# F28x7x_eqep_regs register map
Vendor: Texas Instruments
Peripheral module from a debugger description file (folder C2000).
Address unit: 16 bits
Registers are 16-bit, read-write, no defined reset value unless marked. A register's access mark holds for its fields unless they carry their own. Offsets are as the file gives them; lines under a group give offsets from that group; [hi:lo] are bit positions; {n}, {i} and the like mark numbered series; 'fields as' and 'values as' point back to an identical list; <NAME> marks a mode.

## EQEP_REGS
0x00 QPOSCNT 32-bit — Position Counter
0x02 QPOSINIT 32-bit — Position Counter Init
0x04 QPOSMAX 32-bit — Maximum Position Count
0x06 QPOSCMP 32-bit — Position Compare
0x08 QPOSILAT 32-bit — Index Position Latch
0x0A QPOSSLAT 32-bit — Strobe Position Latch
0x0C QPOSLAT 32-bit — Position Latch
0x0E QUTMR 32-bit — QEP Unit Timer
0x10 QUPRD 32-bit — QEP Unit Period
0x12 QWDTMR — QEP Watchdog Timer
0x13 QWDPRD — QEP Watchdog Period
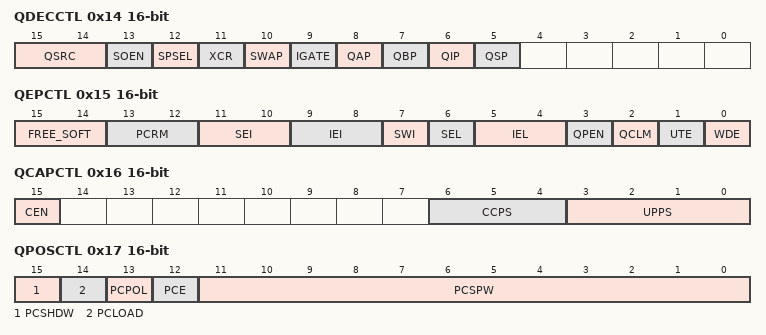
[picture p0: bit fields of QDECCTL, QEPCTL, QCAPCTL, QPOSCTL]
0x14 QDECCTL — Quadrature Decoder Control
  [15:14] QSRC — Position-counter source selection
    0=Quadrature count mode (QCLK = iCLK, QDIR = iDIR); 1=Direction-count mode (QCLK = xCLK, QDIR = xDIR); 2=__2 (UP count mode for frequency measurement (QCLK = xCLK, QDIR = 1)); 3=__3 (DOWN count mode for frequency measurement (QCLK = xCLK, QDIR =)
  [13] SOEN — Sync output-enable
    0=Disable position-compare sync output; 1=Enable position-compare sync output
  [12] SPSEL — Sync output pin selection
    0=Index pin is used for sync output; 1=Strobe pin is used for sync output
  [11] XCR — External Clock Rate
    0=2x resolution: Count the rising/falling edge; 1=1x resolution: Count the rising edge only
  [10] SWAP — CLK/DIR Signal Source for Position Counter
    0=Quadrature-clock inputs are not swapped; 1=Quadrature-clock inputs are swapped
  [9] IGATE — Index pulse gating option
    0=Disable gating of Index pulse; 1=Gate the index pin with strobe
  [8] QAP — QEPA input polarity
    0=No effect; 1=Negates QEPA input
  [7] QBP — QEPB input polarity
    0=No effect; 1=Negates QEPB input
  [6] QIP — QEPI input polarity
    0=No effect; 1=Negates QEPI input
  [5] QSP — QEPS input polarity
    0=No effect; 1=Negates QEPS input
0x15 QEPCTL — QEP Control
  [15:14] FREE_SOFT — Emulation mode
    0=QPOSCNT behavior[[br]]Position counter stops immediately on emu; 1=QPOSCNT behavior[[br]]Position counter continues to count until; 2=__2 (QPOSCNT behavior[[br]]Position counter is unaffected by emulati); 3=__3 (Same as FREE_SOFT_2)
  [13:12] PCRM — Postion counter reset
    0=Position counter reset on an index event; 1=Position counter reset on the maximum position; 2=__2 (Position counter reset on the first index event); 3=__3 (Position counter reset on a unit time event)
  [11:10] SEI — Strobe event init
    0=Does nothing (action disabled); 1=Does nothing (action disabled); 2=__2 (Initializes the position counter on rising edge of the QEPS sig); 3=__3 (Clockwise Direction:[[br]]Initializes the position counter on t)
  [9:8] IEI — Index event init of position count
    0=Do nothing (action disabled); 1=Do nothing (action disabled); 2=__2 (Initializes the position counter on the rising edge of the QEPI); 3=__3 (Initializes the position counter on the falling edge of QEPI si)
  [7] SWI — Software init position counter
    0=Do nothing (action disabled); 1=Initialize position counter (QPOSCNT=QPOSINIT)
  [6] SEL — Strobe event latch
    0=The position counter is latched on the rising edge of QEPS stro; 1=Clockwise Direction:[[br]]Position counter is latched on rising
  [5:4] IEL — Index event latch
    1=Latches position counter on rising edge of the index signal; 2=__2 (Latches position counter on falling edge of the index signal); 3=__3 (Software index marker)
  [3] QPEN — Quadrature postotion counter enable
    0=Reset the eQEP peripheral internal operating flags/read-only re; 1=eQEP position counter is enabled
  [2] QCLM — QEP capture latch mode
    0=Latch on position counter read by CPU; 1=Latch on unit time out
  [1] UTE — QEP unit timer enable
    0=Disable eQEP unit timer; 1=Enable unit timer
  [0] WDE — QEP watchdog enable
    0=Disable the eQEP watchdog timer; 1=Enable the eQEP watchdog timer
0x16 QCAPCTL — Qaudrature Capture Control
  [15] CEN — Enable eQEP capture
    0=eQEP capture unit is disabled; 1=eQEP capture unit is enabled
  [6:4] CCPS — eQEP capture timer clock prescaler
    0=CAPCLK = SYSCLKOUT/1; 1=CAPCLK = SYSCLKOUT/2; 2=__2 (CAPCLK = SYSCLKOUT/4); 3=__3 (CAPCLK = SYSCLKOUT/8); 4=__4 (CAPCLK = SYSCLKOUT/16); 5=__5 (CAPCLK = SYSCLKOUT/32); 6=__6 (CAPCLK = SYSCLKOUT/64); 7=__7 (CAPCLK = SYSCLKOUT/128)
  [3:0] UPPS — Unit position event prescaler
    0=UPEVNT = QCLK/1; 1=UPEVNT = QCLK/2; 2=__2 (UPEVNT = QCLK/4); 3=__3 (UPEVNT = QCLK/8); 4=__4 (UPEVNT = QCLK/16); 5=__5 (UPEVNT = QCLK/32); 6=__6 (UPEVNT = QCLK/64); 7=__7 (UPEVNT = QCLK/128); 8=__8 (UPEVNT = QCLK/256); 9=__9 (UPEVNT = QCLK/512); 10=__16 (UPEVNT = QCLK/1024); 11=__17 (UPEVNT = QCLK/2048); {v}=__{v+6} (Reserved) (v=12..15)
0x17 QPOSCTL — Position Compare Control
  [15] PCSHDW — Position compare of shadow enable
    0=Shadow disabled, load Immediate; 1=Shadow enabled
  [14] PCLOAD — Position compare of shadow load
    0=Load on QPOSCNT = 0; 1=Load when QPOSCNT = QPOSCMP
  [13] PCPOL — Polarity of sync output
    0=Active HIGH pulse output; 1=Active LOW pulse output
  [12] PCE — Position compare enable/disable
    0=Disable position compare unit; 1=Enable position compare unit
  [11:0] PCSPW — Position compare sync pulse width
    0=1 * 4 * SYSCLKOUT cycles; 1=2 * 4 * SYSCLKOUT cycles; 0xFFF=__16533 (4096 * 4 * SYSCLKOUT cycles)
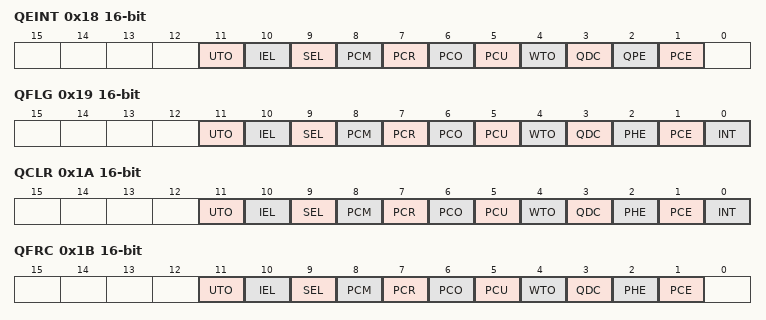
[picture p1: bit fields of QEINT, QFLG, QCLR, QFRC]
0x18 QEINT — QEP Interrupt Control
  [all] fields
    0=Interrupt is disabled; 1=Interrupt is enabled
  [11] UTO — Unit time out interrupt enable
  [10] IEL — Index event latch interrupt enable
  [9] SEL — Strobe event latch interrupt enable
  [8] PCM — Position-compare match interrupt enable
  [7] PCR — Position-compare ready interrupt enable
  [6] PCO — Position counter overflow interrupt enable
  [5] PCU — Position counter underflow interrupt enable
  [4] WTO — Watchdog time out interrupt enable
  [3] QDC — Quadrature direction change interrupt enable
  [2] QPE — Quadrature phase error interrupt enable
  [1] PCE — Position counter error interrupt enable
0x19 QFLG — QEP Interrupt Flag
  [all] fields
    0=No interrupt generated; 1=Interrupt was generated
  [11] UTO — Unit time out interrupt flag
  [10] IEL — Index event latch interrupt flag
  [9] SEL — Strobe event latch interrupt flag
  [8] PCM — eQEP compare match event interrupt flag
  [7] PCR — Position-compare ready interrupt flag
  [6] PCO — Position counter overflow interrupt flag
  [5] PCU — Position counter underflow interrupt flag
  [4] WTO — Watchdog timeout interrupt flag
  [3] QDC — Quadrature direction change interrupt flag
  [2] PHE — Quadrature phase error interrupt flag
  [1] PCE — Position counter error interrupt flag
  [0] INT — Global interrupt status flag
0x1A QCLR — QEP Interrupt Clear
  [all] fields
    0=No effect; 1=Clears the interrupt flag
  [11] UTO — Clear unit time out interrupt flag
  [10] IEL — Clear index event latch interrupt flag
  [9] SEL — Clear strobe event latch interrupt flag
  [8] PCM — Clear eQEP compare match event interrupt flag
  [7] PCR — Clear position-compare ready interrupt flag
  [6] PCO — Clear position counter overflow interrupt flag
  [5] PCU — Clear position counter underflow interrupt flag
  [4] WTO — Clear watchdog timeout interrupt flag
  [3] QDC — Clear quadrature direction change interrupt flag
  [2] PHE — Clear quadrature phase error interrupt flag
  [1] PCE — Clear position counter error interrupt flag
  [0] INT — Global interrupt clear flag
0x1B QFRC — QEP Interrupt Force
  [all] fields
    0=No effect; 1=Force the interrupt
  [11] UTO — Force unit time out interrupt
  [10] IEL — Force index event latch interrupt
  [9] SEL — Force strobe event latch interrupt
  [8] PCM — Force position-compare match interrupt
  [7] PCR — Force position-compare ready interrupt
  [6] PCO — Force position counter overflow interrupt
  [5] PCU — Force position counter underflow interrupt
  [4] WTO — Force watchdog time out interrupt
  [3] QDC — Force quadrature direction change interrupt
  [2] PHE — Force quadrature phase error interrupt
  [1] PCE — Force position counter error interrupt
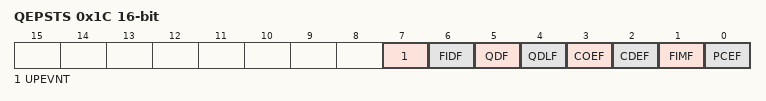
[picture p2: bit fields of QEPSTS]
0x1C QEPSTS — QEP Status
  [7] UPEVNT — Unit position event flag
    0=No unit position event detected; 1=Unit position event detected. Write 1 to clear
  [6] FIDF — The first index marker
    0=Counter-clockwise rotation (or reverse movement) on the first i; 1=Clockwise rotation (or forward movement) on the first index eve
  [5] QDF — Quadrature direction flag
    0=Counter-clockwise rotation (or reverse movement); 1=Clockwise rotation (or forward movement)
  [4] QDLF — eQEP direction latch flag
    0=Counter-clockwise rotation (or reverse movement) on index event; 1=Clockwise rotation (or forward movement) on index event marker
  [3] COEF — Capture overflow error flag
    0=Sticky bit, cleared by writing 1; 1=Overflow occurred in eQEP Capture timer (QEPCTMR)
  [2] CDEF — Capture direction error flag
    0=Sticky bit, cleared by writing 1; 1=Direction change occurred between the capture position event
  [1] FIMF — First index marker flag
    0=Sticky bit, cleared by writing 1; 1=Set by first occurrence of index pulse
  [0] PCEF — Position counter error flag.
    0=No error occurred during the last index transition; 1=Position counter error
0x1D QCTMR — QEP Capture Timer
  [15:0] QCTMR — This register provides time base for edge capture unit.
0x1E QCPRD — QEP Capture Period
  [15:0] QCPRD — Period count value between eQEP position events
0x1F QCTMRLAT — QEP Capture Latch
  [15:0] QCTMRLAT — The eQEP capture timer latch value
0x20 QCPRDLAT — QEP Capture Period Latch
  [15:0] QCPRDLAT — eQEP capture period latch value
